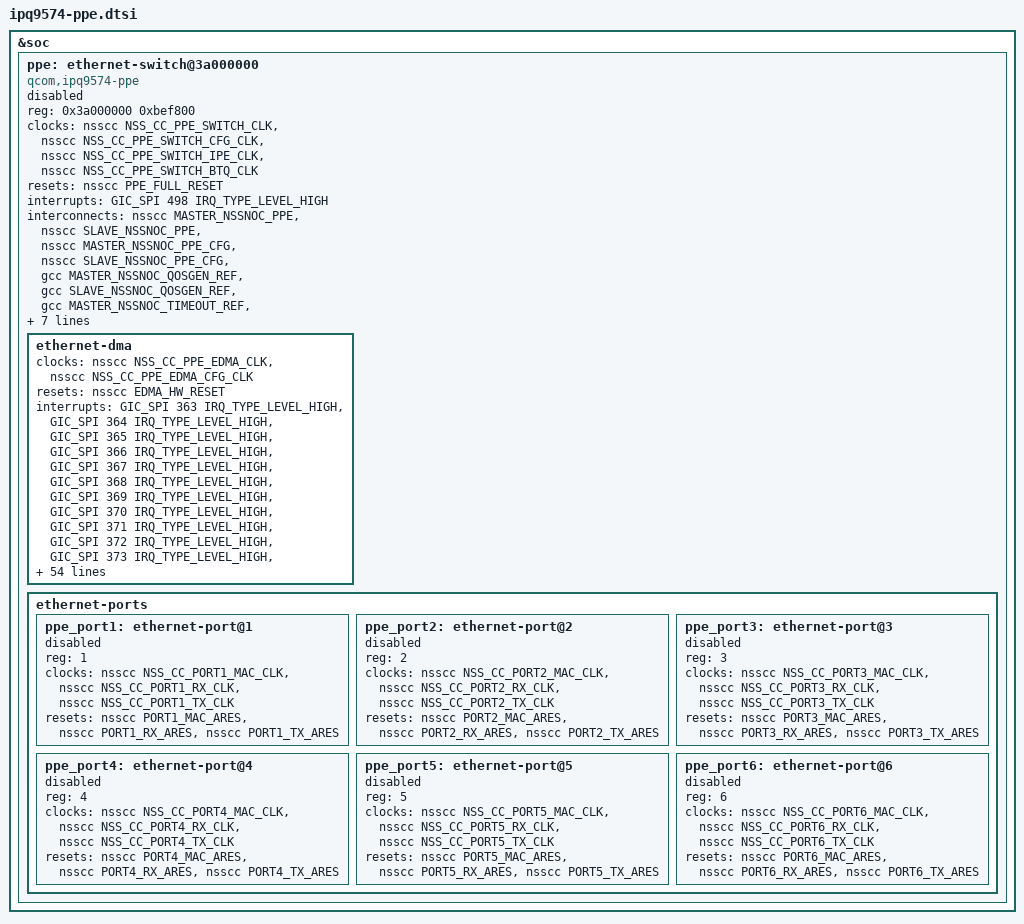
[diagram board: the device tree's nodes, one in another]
// SPDX-License-Identifier: GPL-2.0-only OR BSD-3-Clause
/*
 * IPQ9574 PPE (packet process engine) and its Ethernet DMA.
 */

#include <dt-bindings/clock/qcom,ipq9574-gcc.h>
#include <dt-bindings/interrupt-controller/arm-gic.h>
#include <dt-bindings/clock/qcom,ipq9574-nsscc.h>
#include <dt-bindings/reset/qcom,ipq9574-nsscc.h>

&soc {
	/* The per-port clocks and resets are in the port nodes. A board
	 * enables the ports that it uses and gives each a PHY, a PCS and an
	 * interface mode.
	 */
	ppe: ethernet-switch@3a000000 {
		compatible = "qcom,ipq9574-ppe";
		reg = <0x3a000000 0xbef800>;
		clocks = <&nsscc NSS_CC_PPE_SWITCH_CLK>,
			 <&nsscc NSS_CC_PPE_SWITCH_CFG_CLK>,
			 <&nsscc NSS_CC_PPE_SWITCH_IPE_CLK>,
			 <&nsscc NSS_CC_PPE_SWITCH_BTQ_CLK>;
		clock-names = "ppe", "apb", "ipe", "btq";
		resets = <&nsscc PPE_FULL_RESET>;
		interrupts = <GIC_SPI 498 IRQ_TYPE_LEVEL_HIGH>;
		interconnects = <&nsscc MASTER_NSSNOC_PPE &nsscc SLAVE_NSSNOC_PPE>,
				<&nsscc MASTER_NSSNOC_PPE_CFG &nsscc SLAVE_NSSNOC_PPE_CFG>,
				<&gcc MASTER_NSSNOC_QOSGEN_REF &gcc SLAVE_NSSNOC_QOSGEN_REF>,
				<&gcc MASTER_NSSNOC_TIMEOUT_REF &gcc SLAVE_NSSNOC_TIMEOUT_REF>,
				<&gcc MASTER_MEM_NOC_NSSNOC &gcc SLAVE_MEM_NOC_NSSNOC>,
				<&gcc MASTER_NSSNOC_MEMNOC &gcc SLAVE_NSSNOC_MEMNOC>,
				<&gcc MASTER_NSSNOC_MEM_NOC_1 &gcc SLAVE_NSSNOC_MEM_NOC_1>;
		interconnect-names = "ppe",
				     "ppe_cfg",
				     "qos_gen",
				     "timeout_ref",
				     "nssnoc_memnoc",
				     "memnoc_nssnoc",
				     "memnoc_nssnoc_1";
		status = "disabled";

		ethernet-dma {
			clocks = <&nsscc NSS_CC_PPE_EDMA_CLK>,
				 <&nsscc NSS_CC_PPE_EDMA_CFG_CLK>;
			clock-names = "sys", "apb";
			resets = <&nsscc EDMA_HW_RESET>;
			interrupts = <GIC_SPI 363 IRQ_TYPE_LEVEL_HIGH>,
				     <GIC_SPI 364 IRQ_TYPE_LEVEL_HIGH>,
				     <GIC_SPI 365 IRQ_TYPE_LEVEL_HIGH>,
				     <GIC_SPI 366 IRQ_TYPE_LEVEL_HIGH>,
				     <GIC_SPI 367 IRQ_TYPE_LEVEL_HIGH>,
				     <GIC_SPI 368 IRQ_TYPE_LEVEL_HIGH>,
				     <GIC_SPI 369 IRQ_TYPE_LEVEL_HIGH>,
				     <GIC_SPI 370 IRQ_TYPE_LEVEL_HIGH>,
				     <GIC_SPI 371 IRQ_TYPE_LEVEL_HIGH>,
				     <GIC_SPI 372 IRQ_TYPE_LEVEL_HIGH>,
				     <GIC_SPI 373 IRQ_TYPE_LEVEL_HIGH>,
				     <GIC_SPI 374 IRQ_TYPE_LEVEL_HIGH>,
				     <GIC_SPI 375 IRQ_TYPE_LEVEL_HIGH>,
				     <GIC_SPI 376 IRQ_TYPE_LEVEL_HIGH>,
				     <GIC_SPI 377 IRQ_TYPE_LEVEL_HIGH>,
				     <GIC_SPI 378 IRQ_TYPE_LEVEL_HIGH>,
				     <GIC_SPI 379 IRQ_TYPE_LEVEL_HIGH>,
				     <GIC_SPI 380 IRQ_TYPE_LEVEL_HIGH>,
				     <GIC_SPI 381 IRQ_TYPE_LEVEL_HIGH>,
				     <GIC_SPI 382 IRQ_TYPE_LEVEL_HIGH>,
				     <GIC_SPI 383 IRQ_TYPE_LEVEL_HIGH>,
				     <GIC_SPI 384 IRQ_TYPE_LEVEL_HIGH>,
				     <GIC_SPI 509 IRQ_TYPE_LEVEL_HIGH>,
				     <GIC_SPI 508 IRQ_TYPE_LEVEL_HIGH>,
				     <GIC_SPI 507 IRQ_TYPE_LEVEL_HIGH>,
				     <GIC_SPI 506 IRQ_TYPE_LEVEL_HIGH>,
				     <GIC_SPI 505 IRQ_TYPE_LEVEL_HIGH>,
				     <GIC_SPI 504 IRQ_TYPE_LEVEL_HIGH>,
				     <GIC_SPI 503 IRQ_TYPE_LEVEL_HIGH>,
				     <GIC_SPI 502 IRQ_TYPE_LEVEL_HIGH>,
				     <GIC_SPI 501 IRQ_TYPE_LEVEL_HIGH>,
				     <GIC_SPI 500 IRQ_TYPE_LEVEL_HIGH>,
				     <GIC_SPI 355 IRQ_TYPE_LEVEL_HIGH>,
				     <GIC_SPI 356 IRQ_TYPE_LEVEL_HIGH>,
				     <GIC_SPI 357 IRQ_TYPE_LEVEL_HIGH>,
				     <GIC_SPI 358 IRQ_TYPE_LEVEL_HIGH>,
				     <GIC_SPI 359 IRQ_TYPE_LEVEL_HIGH>,
				     <GIC_SPI 360 IRQ_TYPE_LEVEL_HIGH>,
				     <GIC_SPI 361 IRQ_TYPE_LEVEL_HIGH>,
				     <GIC_SPI 362 IRQ_TYPE_LEVEL_HIGH>,
				     <GIC_SPI 331 IRQ_TYPE_LEVEL_HIGH>,
				     <GIC_SPI 332 IRQ_TYPE_LEVEL_HIGH>,
				     <GIC_SPI 333 IRQ_TYPE_LEVEL_HIGH>,
				     <GIC_SPI 334 IRQ_TYPE_LEVEL_HIGH>,
				     <GIC_SPI 335 IRQ_TYPE_LEVEL_HIGH>,
				     <GIC_SPI 336 IRQ_TYPE_LEVEL_HIGH>,
				     <GIC_SPI 337 IRQ_TYPE_LEVEL_HIGH>,
				     <GIC_SPI 338 IRQ_TYPE_LEVEL_HIGH>,
				     <GIC_SPI 339 IRQ_TYPE_LEVEL_HIGH>,
				     <GIC_SPI 340 IRQ_TYPE_LEVEL_HIGH>,
				     <GIC_SPI 341 IRQ_TYPE_LEVEL_HIGH>,
				     <GIC_SPI 342 IRQ_TYPE_LEVEL_HIGH>,
				     <GIC_SPI 343 IRQ_TYPE_LEVEL_HIGH>,
				     <GIC_SPI 344 IRQ_TYPE_LEVEL_HIGH>,
				     <GIC_SPI 345 IRQ_TYPE_LEVEL_HIGH>,
				     <GIC_SPI 346 IRQ_TYPE_LEVEL_HIGH>,
				     <GIC_SPI 347 IRQ_TYPE_LEVEL_HIGH>,
				     <GIC_SPI 348 IRQ_TYPE_LEVEL_HIGH>,
				     <GIC_SPI 349 IRQ_TYPE_LEVEL_HIGH>,
				     <GIC_SPI 350 IRQ_TYPE_LEVEL_HIGH>,
				     <GIC_SPI 351 IRQ_TYPE_LEVEL_HIGH>,
				     <GIC_SPI 352 IRQ_TYPE_LEVEL_HIGH>,
				     <GIC_SPI 353 IRQ_TYPE_LEVEL_HIGH>,
				     <GIC_SPI 354 IRQ_TYPE_LEVEL_HIGH>,
				     <GIC_SPI 499 IRQ_TYPE_LEVEL_HIGH>;
			interrupt-names = "txcmpl_0",
					"txcmpl_1",
					"txcmpl_2",
					"txcmpl_3",
					"txcmpl_4",
					"txcmpl_5",
					"txcmpl_6",
					"txcmpl_7",
					"txcmpl_8",
					"txcmpl_9",
					"txcmpl_10",
					"txcmpl_11",
					"txcmpl_12",
					"txcmpl_13",
					"txcmpl_14",
					"txcmpl_15",
					"txcmpl_16",
					"txcmpl_17",
					"txcmpl_18",
					"txcmpl_19",
					"txcmpl_20",
					"txcmpl_21",
					"txcmpl_22",
					"txcmpl_23",
					"txcmpl_24",
					"txcmpl_25",
					"txcmpl_26",
					"txcmpl_27",
					"txcmpl_28",
					"txcmpl_29",
					"txcmpl_30",
					"txcmpl_31",
					"rxfill_0",
					"rxfill_1",
					"rxfill_2",
					"rxfill_3",
					"rxfill_4",
					"rxfill_5",
					"rxfill_6",
					"rxfill_7",
					"rxdesc_0",
					"rxdesc_1",
					"rxdesc_2",
					"rxdesc_3",
					"rxdesc_4",
					"rxdesc_5",
					"rxdesc_6",
					"rxdesc_7",
					"rxdesc_8",
					"rxdesc_9",
					"rxdesc_10",
					"rxdesc_11",
					"rxdesc_12",
					"rxdesc_13",
					"rxdesc_14",
					"rxdesc_15",
					"rxdesc_16",
					"rxdesc_17",
					"rxdesc_18",
					"rxdesc_19",
					"rxdesc_20",
					"rxdesc_21",
					"rxdesc_22",
					"rxdesc_23",
					"misc";
		};

		ethernet-ports {
			#address-cells = <1>;
			#size-cells = <0>;

			ppe_port1: ethernet-port@1 {
				reg = <1>;
				clocks = <&nsscc NSS_CC_PORT1_MAC_CLK>,
					 <&nsscc NSS_CC_PORT1_RX_CLK>,
					 <&nsscc NSS_CC_PORT1_TX_CLK>;
				clock-names = "mac", "rx", "tx";
				resets = <&nsscc PORT1_MAC_ARES>,
					 <&nsscc PORT1_RX_ARES>,
					 <&nsscc PORT1_TX_ARES>;
				reset-names = "mac", "rx", "tx";
				status = "disabled";
			};

			ppe_port2: ethernet-port@2 {
				reg = <2>;
				clocks = <&nsscc NSS_CC_PORT2_MAC_CLK>,
					 <&nsscc NSS_CC_PORT2_RX_CLK>,
					 <&nsscc NSS_CC_PORT2_TX_CLK>;
				clock-names = "mac", "rx", "tx";
				resets = <&nsscc PORT2_MAC_ARES>,
					 <&nsscc PORT2_RX_ARES>,
					 <&nsscc PORT2_TX_ARES>;
				reset-names = "mac", "rx", "tx";
				status = "disabled";
			};

			ppe_port3: ethernet-port@3 {
				reg = <3>;
				clocks = <&nsscc NSS_CC_PORT3_MAC_CLK>,
					 <&nsscc NSS_CC_PORT3_RX_CLK>,
					 <&nsscc NSS_CC_PORT3_TX_CLK>;
				clock-names = "mac", "rx", "tx";
				resets = <&nsscc PORT3_MAC_ARES>,
					 <&nsscc PORT3_RX_ARES>,
					 <&nsscc PORT3_TX_ARES>;
				reset-names = "mac", "rx", "tx";
				status = "disabled";
			};

			ppe_port4: ethernet-port@4 {
				reg = <4>;
				clocks = <&nsscc NSS_CC_PORT4_MAC_CLK>,
					 <&nsscc NSS_CC_PORT4_RX_CLK>,
					 <&nsscc NSS_CC_PORT4_TX_CLK>;
				clock-names = "mac", "rx", "tx";
				resets = <&nsscc PORT4_MAC_ARES>,
					 <&nsscc PORT4_RX_ARES>,
					 <&nsscc PORT4_TX_ARES>;
				reset-names = "mac", "rx", "tx";
				status = "disabled";
			};

			ppe_port5: ethernet-port@5 {
				reg = <5>;
				clocks = <&nsscc NSS_CC_PORT5_MAC_CLK>,
					 <&nsscc NSS_CC_PORT5_RX_CLK>,
					 <&nsscc NSS_CC_PORT5_TX_CLK>;
				clock-names = "mac", "rx", "tx";
				resets = <&nsscc PORT5_MAC_ARES>,
					 <&nsscc PORT5_RX_ARES>,
					 <&nsscc PORT5_TX_ARES>;
				reset-names = "mac", "rx", "tx";
				status = "disabled";
			};

			ppe_port6: ethernet-port@6 {
				reg = <6>;
				clocks = <&nsscc NSS_CC_PORT6_MAC_CLK>,
					 <&nsscc NSS_CC_PORT6_RX_CLK>,
					 <&nsscc NSS_CC_PORT6_TX_CLK>;
				clock-names = "mac", "rx", "tx";
				resets = <&nsscc PORT6_MAC_ARES>,
					 <&nsscc PORT6_RX_ARES>,
					 <&nsscc PORT6_TX_ARES>;
				reset-names = "mac", "rx", "tx";
				status = "disabled";
			};
		};
	};
};
